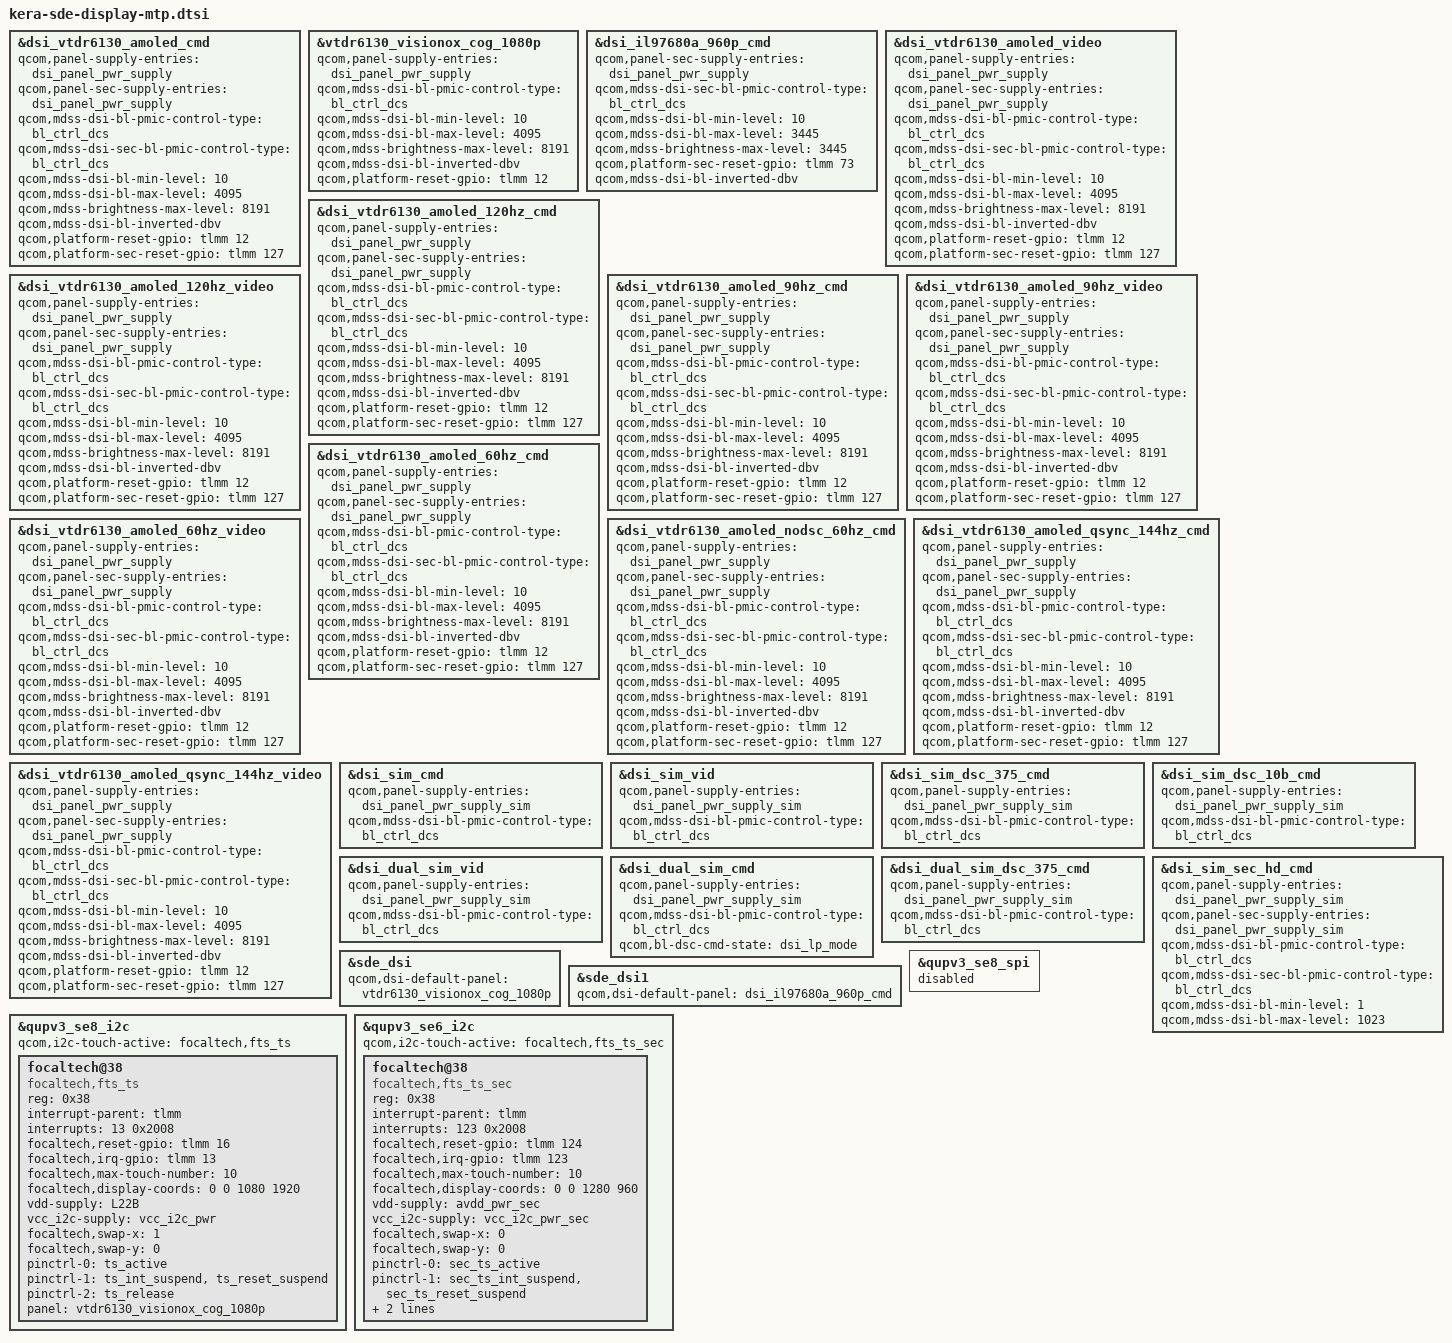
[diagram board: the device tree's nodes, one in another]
// SPDX-License-Identifier: BSD-3-Clause
/*
 * Copyright (c) Qualcomm Technologies, Inc. and/or its subsidiaries.
 */

#include "kera-sde-display.dtsi"

&dsi_vtdr6130_amoled_cmd {
	qcom,panel-supply-entries = <&dsi_panel_pwr_supply>;
	qcom,panel-sec-supply-entries = <&dsi_panel_pwr_supply>;
	qcom,mdss-dsi-bl-pmic-control-type = "bl_ctrl_dcs";
	qcom,mdss-dsi-sec-bl-pmic-control-type = "bl_ctrl_dcs";
	qcom,mdss-dsi-bl-min-level = <10>;
	qcom,mdss-dsi-bl-max-level = <4095>;
	qcom,mdss-brightness-max-level = <8191>;
	qcom,mdss-dsi-bl-inverted-dbv;
	qcom,platform-reset-gpio = <&tlmm 12 0>;
	qcom,platform-sec-reset-gpio = <&tlmm 127 0>;
};

&vtdr6130_visionox_cog_1080p {
       qcom,panel-supply-entries = <&dsi_panel_pwr_supply>;
       qcom,mdss-dsi-bl-pmic-control-type = "bl_ctrl_dcs";
       qcom,mdss-dsi-bl-min-level = <10>;
       qcom,mdss-dsi-bl-max-level = <4095>;
       qcom,mdss-brightness-max-level = <8191>;
       qcom,mdss-dsi-bl-inverted-dbv;
       qcom,platform-reset-gpio = <&tlmm 12 0>;
};

&dsi_il97680a_960p_cmd {
       qcom,panel-sec-supply-entries = <&dsi_panel_pwr_supply>;
       qcom,mdss-dsi-sec-bl-pmic-control-type = "bl_ctrl_dcs";
       qcom,mdss-dsi-bl-min-level = <10>;
       qcom,mdss-dsi-bl-max-level = <3445>;
       qcom,mdss-brightness-max-level = <3445>;
       //qcom,platform-mipi-2v8 = <&tlmm 143 0>;
       //qcom,platform-mipi-1v8 = <&tlmm 70 0>;
       qcom,platform-sec-reset-gpio = <&tlmm 73 0>;
       qcom,mdss-dsi-bl-inverted-dbv;
};

&dsi_vtdr6130_amoled_video {
	qcom,panel-supply-entries = <&dsi_panel_pwr_supply>;
	qcom,panel-sec-supply-entries = <&dsi_panel_pwr_supply>;
	qcom,mdss-dsi-bl-pmic-control-type = "bl_ctrl_dcs";
	qcom,mdss-dsi-sec-bl-pmic-control-type = "bl_ctrl_dcs";
	qcom,mdss-dsi-bl-min-level = <10>;
	qcom,mdss-dsi-bl-max-level = <4095>;
	qcom,mdss-brightness-max-level = <8191>;
	qcom,mdss-dsi-bl-inverted-dbv;
	qcom,platform-reset-gpio = <&tlmm 12 0>;
	qcom,platform-sec-reset-gpio = <&tlmm 127 0>;
};

&dsi_vtdr6130_amoled_120hz_cmd {
	qcom,panel-supply-entries = <&dsi_panel_pwr_supply>;
	qcom,panel-sec-supply-entries = <&dsi_panel_pwr_supply>;
	qcom,mdss-dsi-bl-pmic-control-type = "bl_ctrl_dcs";
	qcom,mdss-dsi-sec-bl-pmic-control-type = "bl_ctrl_dcs";
	qcom,mdss-dsi-bl-min-level = <10>;
	qcom,mdss-dsi-bl-max-level = <4095>;
	qcom,mdss-brightness-max-level = <8191>;
	qcom,mdss-dsi-bl-inverted-dbv;
	qcom,platform-reset-gpio = <&tlmm 12 0>;
	qcom,platform-sec-reset-gpio = <&tlmm 127 0>;
};

&dsi_vtdr6130_amoled_120hz_video {
	qcom,panel-supply-entries = <&dsi_panel_pwr_supply>;
	qcom,panel-sec-supply-entries = <&dsi_panel_pwr_supply>;
	qcom,mdss-dsi-bl-pmic-control-type = "bl_ctrl_dcs";
	qcom,mdss-dsi-sec-bl-pmic-control-type = "bl_ctrl_dcs";
	qcom,mdss-dsi-bl-min-level = <10>;
	qcom,mdss-dsi-bl-max-level = <4095>;
	qcom,mdss-brightness-max-level = <8191>;
	qcom,mdss-dsi-bl-inverted-dbv;
	qcom,platform-reset-gpio = <&tlmm 12 0>;
	qcom,platform-sec-reset-gpio = <&tlmm 127 0>;
};

&dsi_vtdr6130_amoled_90hz_cmd {
	qcom,panel-supply-entries = <&dsi_panel_pwr_supply>;
	qcom,panel-sec-supply-entries = <&dsi_panel_pwr_supply>;
	qcom,mdss-dsi-bl-pmic-control-type = "bl_ctrl_dcs";
	qcom,mdss-dsi-sec-bl-pmic-control-type = "bl_ctrl_dcs";
	qcom,mdss-dsi-bl-min-level = <10>;
	qcom,mdss-dsi-bl-max-level = <4095>;
	qcom,mdss-brightness-max-level = <8191>;
	qcom,mdss-dsi-bl-inverted-dbv;
	qcom,platform-reset-gpio = <&tlmm 12 0>;
	qcom,platform-sec-reset-gpio = <&tlmm 127 0>;
};

&dsi_vtdr6130_amoled_90hz_video {
	qcom,panel-supply-entries = <&dsi_panel_pwr_supply>;
	qcom,panel-sec-supply-entries = <&dsi_panel_pwr_supply>;
	qcom,mdss-dsi-bl-pmic-control-type = "bl_ctrl_dcs";
	qcom,mdss-dsi-sec-bl-pmic-control-type = "bl_ctrl_dcs";
	qcom,mdss-dsi-bl-min-level = <10>;
	qcom,mdss-dsi-bl-max-level = <4095>;
	qcom,mdss-brightness-max-level = <8191>;
	qcom,mdss-dsi-bl-inverted-dbv;
	qcom,platform-reset-gpio = <&tlmm 12 0>;
	qcom,platform-sec-reset-gpio = <&tlmm 127 0>;
};

&dsi_vtdr6130_amoled_60hz_cmd {
	qcom,panel-supply-entries = <&dsi_panel_pwr_supply>;
	qcom,panel-sec-supply-entries = <&dsi_panel_pwr_supply>;
	qcom,mdss-dsi-bl-pmic-control-type = "bl_ctrl_dcs";
	qcom,mdss-dsi-sec-bl-pmic-control-type = "bl_ctrl_dcs";
	qcom,mdss-dsi-bl-min-level = <10>;
	qcom,mdss-dsi-bl-max-level = <4095>;
	qcom,mdss-brightness-max-level = <8191>;
	qcom,mdss-dsi-bl-inverted-dbv;
	qcom,platform-reset-gpio = <&tlmm 12 0>;
	qcom,platform-sec-reset-gpio = <&tlmm 127 0>;
};

&dsi_vtdr6130_amoled_nodsc_60hz_cmd {
	qcom,panel-supply-entries = <&dsi_panel_pwr_supply>;
	qcom,panel-sec-supply-entries = <&dsi_panel_pwr_supply>;
	qcom,mdss-dsi-bl-pmic-control-type = "bl_ctrl_dcs";
	qcom,mdss-dsi-sec-bl-pmic-control-type = "bl_ctrl_dcs";
	qcom,mdss-dsi-bl-min-level = <10>;
	qcom,mdss-dsi-bl-max-level = <4095>;
	qcom,mdss-brightness-max-level = <8191>;
	qcom,mdss-dsi-bl-inverted-dbv;
	qcom,platform-reset-gpio = <&tlmm 12 0>;
	qcom,platform-sec-reset-gpio = <&tlmm 127 0>;
};

&dsi_vtdr6130_amoled_60hz_video {
	qcom,panel-supply-entries = <&dsi_panel_pwr_supply>;
	qcom,panel-sec-supply-entries = <&dsi_panel_pwr_supply>;
	qcom,mdss-dsi-bl-pmic-control-type = "bl_ctrl_dcs";
	qcom,mdss-dsi-sec-bl-pmic-control-type = "bl_ctrl_dcs";
	qcom,mdss-dsi-bl-min-level = <10>;
	qcom,mdss-dsi-bl-max-level = <4095>;
	qcom,mdss-brightness-max-level = <8191>;
	qcom,mdss-dsi-bl-inverted-dbv;
	qcom,platform-reset-gpio = <&tlmm 12 0>;
	qcom,platform-sec-reset-gpio = <&tlmm 127 0>;
};

&dsi_vtdr6130_amoled_qsync_144hz_cmd {
	qcom,panel-supply-entries = <&dsi_panel_pwr_supply>;
	qcom,panel-sec-supply-entries = <&dsi_panel_pwr_supply>;
	qcom,mdss-dsi-bl-pmic-control-type = "bl_ctrl_dcs";
	qcom,mdss-dsi-sec-bl-pmic-control-type = "bl_ctrl_dcs";
	qcom,mdss-dsi-bl-min-level = <10>;
	qcom,mdss-dsi-bl-max-level = <4095>;
	qcom,mdss-brightness-max-level = <8191>;
	qcom,mdss-dsi-bl-inverted-dbv;
	qcom,platform-reset-gpio = <&tlmm 12 0>;
	qcom,platform-sec-reset-gpio = <&tlmm 127 0>;
};

&dsi_vtdr6130_amoled_qsync_144hz_video {
	qcom,panel-supply-entries = <&dsi_panel_pwr_supply>;
	qcom,panel-sec-supply-entries = <&dsi_panel_pwr_supply>;
	qcom,mdss-dsi-bl-pmic-control-type = "bl_ctrl_dcs";
	qcom,mdss-dsi-sec-bl-pmic-control-type = "bl_ctrl_dcs";
	qcom,mdss-dsi-bl-min-level = <10>;
	qcom,mdss-dsi-bl-max-level = <4095>;
	qcom,mdss-brightness-max-level = <8191>;
	qcom,mdss-dsi-bl-inverted-dbv;
	qcom,platform-reset-gpio = <&tlmm 12 0>;
	qcom,platform-sec-reset-gpio = <&tlmm 127 0>;
};

&dsi_sim_cmd {
	qcom,panel-supply-entries = <&dsi_panel_pwr_supply_sim>;
	qcom,mdss-dsi-bl-pmic-control-type = "bl_ctrl_dcs";
};

&dsi_sim_vid {
	qcom,panel-supply-entries = <&dsi_panel_pwr_supply_sim>;
	qcom,mdss-dsi-bl-pmic-control-type = "bl_ctrl_dcs";
};

&dsi_sim_dsc_375_cmd {
	qcom,panel-supply-entries = <&dsi_panel_pwr_supply_sim>;
	qcom,mdss-dsi-bl-pmic-control-type = "bl_ctrl_dcs";
};

&dsi_sim_dsc_10b_cmd {
	qcom,panel-supply-entries = <&dsi_panel_pwr_supply_sim>;
	qcom,mdss-dsi-bl-pmic-control-type = "bl_ctrl_dcs";
};

&dsi_dual_sim_vid {
	qcom,panel-supply-entries = <&dsi_panel_pwr_supply_sim>;
	qcom,mdss-dsi-bl-pmic-control-type = "bl_ctrl_dcs";
};

&dsi_dual_sim_cmd {
	qcom,panel-supply-entries = <&dsi_panel_pwr_supply_sim>;
	qcom,mdss-dsi-bl-pmic-control-type = "bl_ctrl_dcs";
	qcom,bl-dsc-cmd-state = "dsi_lp_mode";
};

&dsi_dual_sim_dsc_375_cmd {
	qcom,panel-supply-entries = <&dsi_panel_pwr_supply_sim>;
	qcom,mdss-dsi-bl-pmic-control-type = "bl_ctrl_dcs";
};

&dsi_sim_sec_hd_cmd {
	qcom,panel-supply-entries = <&dsi_panel_pwr_supply_sim>;
	qcom,panel-sec-supply-entries = <&dsi_panel_pwr_supply_sim>;
	qcom,mdss-dsi-bl-pmic-control-type = "bl_ctrl_dcs";
	qcom,mdss-dsi-sec-bl-pmic-control-type = "bl_ctrl_dcs";
	qcom,mdss-dsi-bl-min-level = <1>;
	qcom,mdss-dsi-bl-max-level = <1023>;
};

&sde_dsi {
	qcom,dsi-default-panel = <&vtdr6130_visionox_cog_1080p>;
	status = "okay";
};

&sde_dsi1 {
    qcom,dsi-default-panel = <&dsi_il97680a_960p_cmd>;
	status = "okay";
 };

 &qupv3_se8_spi {
	status = "disabled";
};

&qupv3_se8_i2c {                                                                                                                                                                                             
  status = "okay"; 
  
  qcom,i2c-touch-active="focaltech,fts_ts";

  focaltech@38 {
    compatible = "focaltech,fts_ts";
    reg = <0x38>;
    interrupt-parent = <&tlmm>;
    interrupts = <13 0x2008>;
    focaltech,reset-gpio = <&tlmm 16 0x00>;
    focaltech,irq-gpio = <&tlmm 13 0x2008>;
    focaltech,max-touch-number = <10>;
    focaltech,display-coords = <0 0 1080 1920>;
	vdd-supply = <&L22B>;
	vcc_i2c-supply = <&vcc_i2c_pwr>;
	focaltech,swap-x = <1>;
	focaltech,swap-y = <0>;

    pinctrl-names = "pmx_ts_active","pmx_ts_suspend","pmx_ts_release";
    pinctrl-0 = <&ts_active>;
    pinctrl-1 = <&ts_int_suspend &ts_reset_suspend>;
    pinctrl-2 = <&ts_release>;

    panel = <&vtdr6130_visionox_cog_1080p>;
  };

};
 
&qupv3_se6_i2c {                                                                                                                                                                                             
  status = "okay"; 
 qcom,i2c-touch-active="focaltech,fts_ts_sec";

  focaltech@38 {
    compatible = "focaltech,fts_ts_sec";
    reg = <0x38>;
    interrupt-parent = <&tlmm>;
    interrupts = <123 0x2008>;
    focaltech,reset-gpio = <&tlmm 124 0x00>;
    focaltech,irq-gpio = <&tlmm 123 0x2008>;
    focaltech,max-touch-number = <10>;
    focaltech,display-coords = <0 0 1280 960>;
	vdd-supply = <&avdd_pwr_sec>;
	vcc_i2c-supply = <&vcc_i2c_pwr_sec>;
	focaltech,swap-x = <0>;
	focaltech,swap-y = <0>;

    pinctrl-names = "pmx_sec_ts_active","pmx_sec_ts_suspend","pmx_sec_ts_release";
    pinctrl-0 = <&sec_ts_active>;
    pinctrl-1 = <&sec_ts_int_suspend &sec_ts_reset_suspend>;
    pinctrl-2 = <&sec_ts_release>;

    panel = <&dsi_il97680a_960p_cmd>;
  };
};
